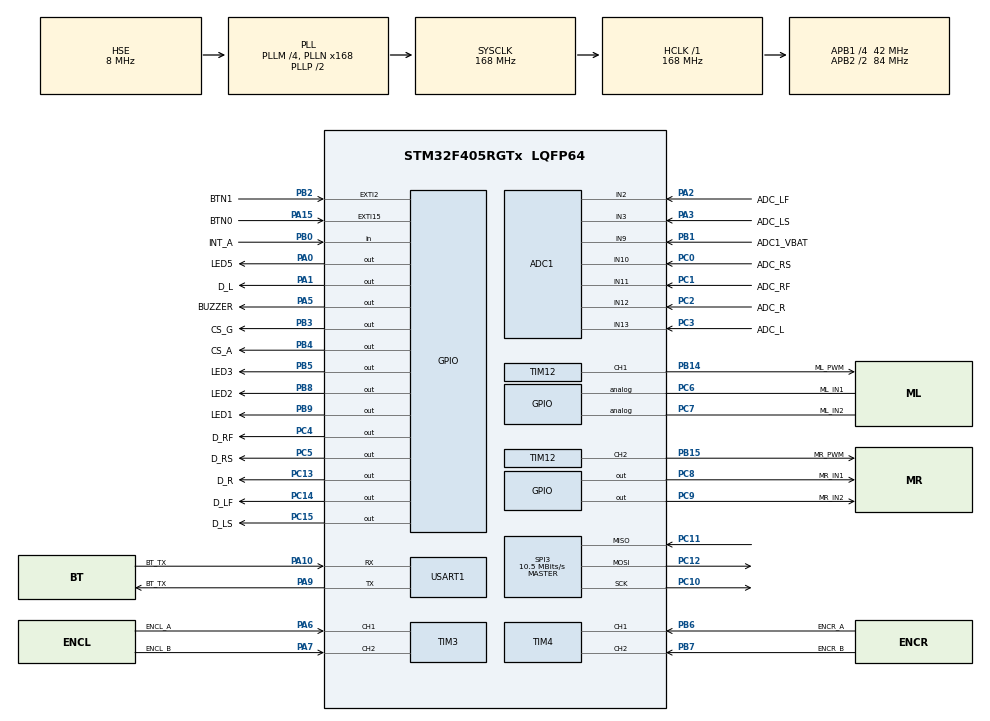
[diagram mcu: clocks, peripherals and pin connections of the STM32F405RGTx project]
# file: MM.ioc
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ADC1.Channel-8\#ChannelRegularConversion=ADC_CHANNEL_VREFINT
ADC1.ClockPrescaler=ADC_CLOCKPRESCALER_PCLK_DIV4
ADC1.ContinuousConvMode=DISABLE
ADC1.DMAContinuousRequests=DISABLE
ADC1.DataAlign=ADC_DATAALIGN_RIGHT
ADC1.DiscontinuousConvMode=DISABLE
ADC1.EOCSelection=EOC_SINGLE_CONV
ADC1.EnableAnalogWatchDog=false
ADC1.ExternalTrigConvEdge=ADC_EXTERNALTRIGCONVEDGE_NONE
ADC1.InjNumberOfConversion=0
ADC1.NbrOfConversion=1
ADC1.NbrOfConversionFlag=1
ADC1.Rank-8\#ChannelRegularConversion=1
ADC1.Resolution=ADC_RESOLUTION12b
ADC1.SamplingTime-8\#ChannelRegularConversion=ADC_SAMPLETIME_3CYCLES
ADC1.ScanConvMode=DISABLE
ADC1.master=1
Mcu.Family=STM32F4
Mcu.Name=STM32F405RGTx
Mcu.Package=LQFP64
NVIC.ADC_IRQn=true\:10\:0\:true
NVIC.EXTI15_10_IRQn=true\:15\:0\:true
NVIC.EXTI2_IRQn=true\:15\:0\:true
NVIC.PriorityGroup=NVIC_PRIORITYGROUP_4
NVIC.SPI3_IRQn=true\:5\:0\:true
NVIC.USART1_IRQn=true\:5\:0\:true
PA0-WKUP.GPIO_Label=LED5
PA0-WKUP.Signal=GPIO_Output
PA1.GPIO_Label=D_L
PA1.Signal=GPIO_Output
PA10.GPIO_Label=BT_TX
PA10.Mode=Asynchronous
PA10.Signal=USART1_RX
PA13.Mode=Serial-Wire
PA13.Signal=SYS_JTMS-SWDIO
PA14.Mode=Serial-Wire
PA14.Signal=SYS_JTCK-SWCLK
PA15.GPIO_Label=BTN0
PA15.Signal=GPXTI15
PA2.GPIO_Label=ADC_LF
PA2.Signal=ADCx_IN2
PA3.GPIO_Label=ADC_LS
PA3.Signal=ADCx_IN3
PA5.GPIO_Label=BUZZER
PA5.Signal=GPIO_Output
PA6.GPIO_Label=ENCL_A
PA6.Signal=S_TIM3_CH1
PA7.GPIO_Label=ENCL_B
PA7.Signal=S_TIM3_CH2
PA9.GPIO_Label=BT_TX
PA9.Mode=Asynchronous
PA9.Signal=USART1_TX
PB0.GPIO_Label=INT_A
PB0.Signal=GPIO_Input
PB1.GPIO_Label=ADC1_VBAT
PB1.Signal=ADCx_IN9
PB14.GPIO_Label=ML_PWM
PB14.Signal=S_TIM12_CH1
PB15.GPIO_Label=MR_PWM
PB15.Signal=S_TIM12_CH2
PB2.GPIO_Label=BTN1
PB2.Signal=GPXTI2
PB3.GPIO_Label=CS_G
PB3.Signal=GPIO_Output
PB4.GPIO_Label=CS_A
PB4.Signal=GPIO_Output
PB5.GPIO_Label=LED3
PB5.Signal=GPIO_Output
PB6.GPIO_Label=ENCR_A
PB6.Signal=S_TIM4_CH1
PB7.GPIO_Label=ENCR_B
PB7.Signal=S_TIM4_CH2
PB8.GPIO_Label=LED2
PB8.Signal=GPIO_Output
PB9.GPIO_Label=LED1
PB9.Signal=GPIO_Output
PC0.GPIO_Label=ADC_RS
PC0.Signal=ADCx_IN10
PC1.GPIO_Label=ADC_RF
PC1.Signal=ADCx_IN11
PC10.Mode=Full_Duplex_Master
PC10.Signal=SPI3_SCK
PC11.Mode=Full_Duplex_Master
PC11.Signal=SPI3_MISO
PC12.Mode=Full_Duplex_Master
PC12.Signal=SPI3_MOSI
PC13-ANTI_TAMP.GPIO_Label=D_R
PC13-ANTI_TAMP.Signal=GPIO_Output
PC14-OSC32_IN.GPIO_Label=D_LF
PC14-OSC32_IN.Signal=GPIO_Output
PC15-OSC32_OUT.GPIO_Label=D_LS
PC15-OSC32_OUT.Signal=GPIO_Output
PC2.GPIO_Label=ADC_R
PC2.Signal=ADCx_IN12
PC3.GPIO_Label=ADC_L
PC3.Signal=ADCx_IN13
PC4.GPIO_Label=D_RF
PC4.Signal=GPIO_Output
PC5.GPIO_Label=D_RS
PC5.Signal=GPIO_Output
PC6.GPIO_Label=ML_IN1
PC6.Signal=GPIO_Analog
PC7.GPIO_Label=ML_IN2
PC7.Signal=GPIO_Analog
PC8.GPIO_Label=MR_IN1
PC8.Signal=GPIO_Output
PC9.GPIO_Label=MR_IN2
PC9.Signal=GPIO_Output
PH0-OSC_IN.Mode=HSE-External-Oscillator
PH0-OSC_IN.Signal=RCC_OSC_IN
PH1-OSC_OUT.Mode=HSE-External-Oscillator
PH1-OSC_OUT.Signal=RCC_OSC_OUT
ProjectManager.HeapSize=0x400
ProjectManager.StackSize=0x200
ProjectManager.TargetToolchain=MDK-ARM V5
RCC.48MHZClocksFreq_Value=84000000
RCC.AHBFreq_Value=168000000
RCC.APB1CLKDivider=RCC_HCLK_DIV4
RCC.APB1Freq_Value=42000000
RCC.APB1TimFreq_Value=84000000
RCC.APB2CLKDivider=RCC_HCLK_DIV2
RCC.APB2Freq_Value=84000000
RCC.APB2TimFreq_Value=168000000
RCC.CortexFreq_Value=168000000
RCC.HCLKFreq_Value=168000000
RCC.HSE_VALUE=8000000
RCC.HSI_VALUE=16000000
RCC.LSE_VALUE=32768
RCC.PLLM=4
RCC.PLLN=168
RCC.PLLSourceVirtual=RCC_PLLSOURCE_HSE
RCC.SYSCLKFreq_VALUE=168000000
RCC.SYSCLKSource=RCC_SYSCLKSOURCE_PLLCLK
RCC.VCOOutputFreq_Value=336000000
SH.ADCx_IN10.0=ADC1_IN10,IN10
SH.ADCx_IN11.0=ADC1_IN11,IN11
SH.ADCx_IN12.0=ADC1_IN12,IN12
SH.ADCx_IN13.0=ADC1_IN13,IN13
SH.ADCx_IN2.0=ADC1_IN2,IN2
SH.ADCx_IN3.0=ADC1_IN3,IN3
SH.ADCx_IN9.0=ADC1_IN9,IN9
SH.S_TIM12_CH1.0=TIM12_CH1,PWM Generation1 CH1
SH.S_TIM12_CH2.0=TIM12_CH2,PWM Generation2 CH2
SH.S_TIM3_CH1.0=TIM3_CH1,Encoder_Interface
SH.S_TIM3_CH2.0=TIM3_CH2,Encoder_Interface
SH.S_TIM4_CH1.0=TIM4_CH1,Encoder_Interface
SH.S_TIM4_CH2.0=TIM4_CH2,Encoder_Interface
SPI3.BaudRatePrescaler=SPI_BAUDRATEPRESCALER_4
SPI3.CalculateBaudRate=10.5 MBits/s
SPI3.Mode=SPI_MODE_MASTER
TIM12.Channel-PWM\ Generation2\ CH2=TIM_CHANNEL_2
VP_ADC1_TempSens_Input.Mode=IN-TempSens
VP_ADC1_Vref_Input.Mode=IN-Vrefint
board=MM

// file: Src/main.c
/**
  ******************************************************************************
  * File Name          : main.c
  * Description        : Main program body
  ******************************************************************************
  *
  * COPYRIGHT(c) 2016 STMicroelectronics
  *
  * Redistribution and use in source and binary forms, with or without modification,
  * are permitted provided that the following conditions are met:
  *   1. Redistributions of source code must retain the above copyright notice,
  *      this list of conditions and the following disclaimer.
  *   2. Redistributions in binary form must reproduce the above copyright notice,
  *      this list of conditions and the following disclaimer in the documentation
  *      and/or other materials provided with the distribution.
  *   3. Neither the name of STMicroelectronics nor the names of its contributors
  *      may be used to endorse or promote products derived from this software
  *      without specific prior written permission.
  *
  * THIS SOFTWARE IS PROVIDED BY THE COPYRIGHT HOLDERS AND CONTRIBUTORS "AS IS"
  * AND ANY EXPRESS OR IMPLIED WARRANTIES, INCLUDING, BUT NOT LIMITED TO, THE
  * IMPLIED WARRANTIES OF MERCHANTABILITY AND FITNESS FOR A PARTICULAR PURPOSE ARE
  * DISCLAIMED. IN NO EVENT SHALL THE COPYRIGHT HOLDER OR CONTRIBUTORS BE LIABLE
  * FOR ANY DIRECT, INDIRECT, INCIDENTAL, SPECIAL, EXEMPLARY, OR CONSEQUENTIAL
  * DAMAGES (INCLUDING, BUT NOT LIMITED TO, PROCUREMENT OF SUBSTITUTE GOODS OR
  * SERVICES; LOSS OF USE, DATA, OR PROFITS; OR BUSINESS INTERRUPTION) HOWEVER
  * CAUSED AND ON ANY THEORY OF LIABILITY, WHETHER IN CONTRACT, STRICT LIABILITY,
  * OR TORT (INCLUDING NEGLIGENCE OR OTHERWISE) ARISING IN ANY WAY OUT OF THE USE
  * OF THIS SOFTWARE, EVEN IF ADVISED OF THE POSSIBILITY OF SUCH DAMAGE.
  *
  ******************************************************************************
  */
#include "stm32f4xx_hal.h"

ADC_HandleTypeDef hadc1;

SPI_HandleTypeDef hspi3;

TIM_HandleTypeDef htim3;
TIM_HandleTypeDef htim4;
TIM_HandleTypeDef htim12;

UART_HandleTypeDef huart1;

/* USER CODE BEGIN PV */
/* Private variables ---------------------------------------------------------*/
#define BUFFERSIZE 16
/* USER CODE END PV */

void SystemClock_Config(void);
static void MX_GPIO_Init(void);
static void MX_ADC1_Init(void);
static void MX_SPI3_Init(void);
static void MX_TIM3_Init(void);
static void MX_TIM4_Init(void);
static void MX_TIM12_Init(void);
static void MX_USART1_UART_Init(void);

void HAL_TIM_MspPostInit(TIM_HandleTypeDef *htim);

/* USER CODE BEGIN PFP */
/* Private function prototypes -----------------------------------------------*/

/* USER CODE END PFP */

/* USER CODE BEGIN 0 */

uint8_t aTxBuffer[] = "****SPI - Two Boards communication based on DMA **** SPI Message ******** SPI Message ******** SPI Message ****";
uint8_t aRxBuffer[BUFFERSIZE];
/* USER CODE END 0 */

int main(void)
{

  /* MCU Configuration----------------------------------------------------------*/

  /* Reset of all peripherals, Initializes the Flash interface and the Systick. */
  HAL_Init();

  /* Configure the system clock */
  SystemClock_Config();

  /* Initialize all configured peripherals */
  MX_GPIO_Init();
  MX_ADC1_Init();
  MX_SPI3_Init();
  MX_TIM3_Init();
  MX_TIM4_Init();
  MX_TIM12_Init();
  MX_USART1_UART_Init();

  /* Infinite loop */
  while (1)
  {
		HAL_SPI_TransmitReceive_DMA(&hspi3, (uint8_t*)aTxBuffer, (uint8_t *)aRxBuffer, BUFFERSIZE);
	HAL_Delay(2000);
  }

}

/** System Clock Configuration
*/
void SystemClock_Config(void)
{

  RCC_OscInitTypeDef RCC_OscInitStruct;
  RCC_ClkInitTypeDef RCC_ClkInitStruct;

  __PWR_CLK_ENABLE();

  __HAL_PWR_VOLTAGESCALING_CONFIG(PWR_REGULATOR_VOLTAGE_SCALE1);

  RCC_OscInitStruct.OscillatorType = RCC_OSCILLATORTYPE_HSE;
  RCC_OscInitStruct.HSEState = RCC_HSE_ON;
  RCC_OscInitStruct.PLL.PLLState = RCC_PLL_ON;
  RCC_OscInitStruct.PLL.PLLSource = RCC_PLLSOURCE_HSE;
  RCC_OscInitStruct.PLL.PLLM = 4;
  RCC_OscInitStruct.PLL.PLLN = 168;
  RCC_OscInitStruct.PLL.PLLP = RCC_PLLP_DIV2;
  RCC_OscInitStruct.PLL.PLLQ = 4;
  HAL_RCC_OscConfig(&RCC_OscInitStruct);

  RCC_ClkInitStruct.ClockType = RCC_CLOCKTYPE_HCLK|RCC_CLOCKTYPE_SYSCLK
                              |RCC_CLOCKTYPE_PCLK1|RCC_CLOCKTYPE_PCLK2;
  RCC_ClkInitStruct.SYSCLKSource = RCC_SYSCLKSOURCE_PLLCLK;
  RCC_ClkInitStruct.AHBCLKDivider = RCC_SYSCLK_DIV1;
  RCC_ClkInitStruct.APB1CLKDivider = RCC_HCLK_DIV4;
  RCC_ClkInitStruct.APB2CLKDivider = RCC_HCLK_DIV2;
  HAL_RCC_ClockConfig(&RCC_ClkInitStruct, FLASH_LATENCY_5);

  HAL_SYSTICK_Config(HAL_RCC_GetHCLKFreq()/1000);

  HAL_SYSTICK_CLKSourceConfig(SYSTICK_CLKSOURCE_HCLK);

  /* SysTick_IRQn interrupt configuration */
  HAL_NVIC_SetPriority(SysTick_IRQn, 0, 0);
}

/* ADC1 init function */
void MX_ADC1_Init(void)
{

  ADC_ChannelConfTypeDef sConfig;

    /**Configure the global features of the ADC (Clock, Resolution, Data Alignment and number of conversion)
    */
  hadc1.Instance = ADC1;
  hadc1.Init.ClockPrescaler = ADC_CLOCKPRESCALER_PCLK_DIV4;
  hadc1.Init.Resolution = ADC_RESOLUTION12b;
  hadc1.Init.ScanConvMode = DISABLE;
  hadc1.Init.ContinuousConvMode = DISABLE;
  hadc1.Init.DiscontinuousConvMode = DISABLE;
  hadc1.Init.ExternalTrigConvEdge = ADC_EXTERNALTRIGCONVEDGE_NONE;
  hadc1.Init.DataAlign = ADC_DATAALIGN_RIGHT;
  hadc1.Init.NbrOfConversion = 1;
  hadc1.Init.DMAContinuousRequests = DISABLE;
  hadc1.Init.EOCSelection = EOC_SINGLE_CONV;
  HAL_ADC_Init(&hadc1);

    /**Configure for the selected ADC regular channel its corresponding rank in the sequencer and its sample time.
    */
  sConfig.Channel = ADC_CHANNEL_VREFINT;
  sConfig.Rank = 1;
  sConfig.SamplingTime = ADC_SAMPLETIME_3CYCLES;
  HAL_ADC_ConfigChannel(&hadc1, &sConfig);

}

/* SPI3 init function */
void MX_SPI3_Init(void)
{

  hspi3.Instance = SPI3;
  hspi3.Init.Mode = SPI_MODE_MASTER;
  hspi3.Init.Direction = SPI_DIRECTION_2LINES;
  hspi3.Init.DataSize = SPI_DATASIZE_8BIT;
  hspi3.Init.CLKPolarity = SPI_POLARITY_LOW;
  hspi3.Init.CLKPhase = SPI_PHASE_1EDGE;
  hspi3.Init.NSS = SPI_NSS_SOFT;
  hspi3.Init.BaudRatePrescaler = SPI_BAUDRATEPRESCALER_4;
  hspi3.Init.FirstBit = SPI_FIRSTBIT_MSB;
  hspi3.Init.TIMode = SPI_TIMODE_DISABLED;
  hspi3.Init.CRCCalculation = SPI_CRCCALCULATION_DISABLED;
  hspi3.Init.CRCPolynomial = 10;
  HAL_SPI_Init(&hspi3);

}

/* TIM3 init function */
void MX_TIM3_Init(void)
{

  TIM_Encoder_InitTypeDef sConfig;
  TIM_MasterConfigTypeDef sMasterConfig;

  htim3.Instance = TIM3;
  htim3.Init.Prescaler = 0;
  htim3.Init.CounterMode = TIM_COUNTERMODE_UP;
  htim3.Init.Period = 0;
  htim3.Init.ClockDivision = TIM_CLOCKDIVISION_DIV1;
  sConfig.EncoderMode = TIM_ENCODERMODE_TI1;
  sConfig.IC1Polarity = TIM_ICPOLARITY_RISING;
  sConfig.IC1Selection = TIM_ICSELECTION_DIRECTTI;
  sConfig.IC1Prescaler = TIM_ICPSC_DIV1;
  sConfig.IC1Filter = 0;
  sConfig.IC2Polarity = TIM_ICPOLARITY_RISING;
  sConfig.IC2Selection = TIM_ICSELECTION_DIRECTTI;
  sConfig.IC2Prescaler = TIM_ICPSC_DIV1;
  sConfig.IC2Filter = 0;
  HAL_TIM_Encoder_Init(&htim3, &sConfig);

  sMasterConfig.MasterOutputTrigger = TIM_TRGO_RESET;
  sMasterConfig.MasterSlaveMode = TIM_MASTERSLAVEMODE_DISABLE;
  HAL_TIMEx_MasterConfigSynchronization(&htim3, &sMasterConfig);

}

/* TIM4 init function */
void MX_TIM4_Init(void)
{

  TIM_Encoder_InitTypeDef sConfig;
  TIM_MasterConfigTypeDef sMasterConfig;

  htim4.Instance = TIM4;
  htim4.Init.Prescaler = 0;
  htim4.Init.CounterMode = TIM_COUNTERMODE_UP;
  htim4.Init.Period = 0;
  htim4.Init.ClockDivision = TIM_CLOCKDIVISION_DIV1;
  sConfig.EncoderMode = TIM_ENCODERMODE_TI1;
  sConfig.IC1Polarity = TIM_ICPOLARITY_RISING;
  sConfig.IC1Selection = TIM_ICSELECTION_DIRECTTI;
  sConfig.IC1Prescaler = TIM_ICPSC_DIV1;
  sConfig.IC1Filter = 0;
  sConfig.IC2Polarity = TIM_ICPOLARITY_RISING;
  sConfig.IC2Selection = TIM_ICSELECTION_DIRECTTI;
  sConfig.IC2Prescaler = TIM_ICPSC_DIV1;
  sConfig.IC2Filter = 0;
  HAL_TIM_Encoder_Init(&htim4, &sConfig);

  sMasterConfig.MasterOutputTrigger = TIM_TRGO_RESET;
  sMasterConfig.MasterSlaveMode = TIM_MASTERSLAVEMODE_DISABLE;
  HAL_TIMEx_MasterConfigSynchronization(&htim4, &sMasterConfig);

}

/* TIM12 init function */
void MX_TIM12_Init(void)
{

  TIM_OC_InitTypeDef sConfigOC;

  htim12.Instance = TIM12;
  htim12.Init.Prescaler = 0;
  htim12.Init.CounterMode = TIM_COUNTERMODE_UP;
  htim12.Init.Period = 0;
  htim12.Init.ClockDivision = TIM_CLOCKDIVISION_DIV1;
  HAL_TIM_PWM_Init(&htim12);

  sConfigOC.OCMode = TIM_OCMODE_PWM1;
  sConfigOC.Pulse = 0;
  sConfigOC.OCPolarity = TIM_OCPOLARITY_HIGH;
  sConfigOC.OCFastMode = TIM_OCFAST_DISABLE;
  HAL_TIM_PWM_ConfigChannel(&htim12, &sConfigOC, TIM_CHANNEL_1);

  HAL_TIM_PWM_ConfigChannel(&htim12, &sConfigOC, TIM_CHANNEL_2);

  HAL_TIM_MspPostInit(&htim12);

}

/* USART1 init function */
void MX_USART1_UART_Init(void)
{

  huart1.Instance = USART1;
  huart1.Init.BaudRate = 115200;
  huart1.Init.WordLength = UART_WORDLENGTH_8B;
  huart1.Init.StopBits = UART_STOPBITS_1;
  huart1.Init.Parity = UART_PARITY_NONE;
  huart1.Init.Mode = UART_MODE_TX_RX;
  huart1.Init.HwFlowCtl = UART_HWCONTROL_NONE;
  huart1.Init.OverSampling = UART_OVERSAMPLING_16;
  HAL_UART_Init(&huart1);

}

/** Configure pins as
        * Analog
        * Input
        * Output
        * EVENT_OUT
        * EXTI
*/
void MX_GPIO_Init(void)
{

  GPIO_InitTypeDef GPIO_InitStruct;

  /* GPIO Ports Clock Enable */
  __GPIOC_CLK_ENABLE();
  __GPIOH_CLK_ENABLE();
  __GPIOA_CLK_ENABLE();
  __GPIOB_CLK_ENABLE();

  /*Configure GPIO pin Output Level */
  HAL_GPIO_WritePin(GPIOC, D_R_Pin|D_LF_Pin|D_LS_Pin|D_RF_Pin
                          |D_RS_Pin|MR_IN1_Pin|MR_IN2_Pin, GPIO_PIN_RESET);

  /*Configure GPIO pin Output Level */
  HAL_GPIO_WritePin(GPIOA, LED5_Pin|D_L_Pin|BUZZER_Pin, GPIO_PIN_RESET);

  /*Configure GPIO pin Output Level */
  HAL_GPIO_WritePin(GPIOB, CS_G_Pin|CS_A_Pin|LED3_Pin|LED2_Pin
                          |LED1_Pin, GPIO_PIN_RESET);

  /*Configure GPIO pins : D_R_Pin D_LF_Pin D_LS_Pin D_RF_Pin
                           D_RS_Pin MR_IN1_Pin MR_IN2_Pin */
  GPIO_InitStruct.Pin = D_R_Pin|D_LF_Pin|D_LS_Pin|D_RF_Pin
                          |D_RS_Pin|MR_IN1_Pin|MR_IN2_Pin;
  GPIO_InitStruct.Mode = GPIO_MODE_OUTPUT_PP;
  GPIO_InitStruct.Pull = GPIO_NOPULL;
  GPIO_InitStruct.Speed = GPIO_SPEED_LOW;
  HAL_GPIO_Init(GPIOC, &GPIO_InitStruct);

  /*Configure GPIO pins : LED5_Pin D_L_Pin BUZZER_Pin */
  GPIO_InitStruct.Pin = LED5_Pin|D_L_Pin|BUZZER_Pin;
  GPIO_InitStruct.Mode = GPIO_MODE_OUTPUT_PP;
  GPIO_InitStruct.Pull = GPIO_NOPULL;
  GPIO_InitStruct.Speed = GPIO_SPEED_LOW;
  HAL_GPIO_Init(GPIOA, &GPIO_InitStruct);

  /*Configure GPIO pin : INT_A_Pin */
  GPIO_InitStruct.Pin = INT_A_Pin;
  GPIO_InitStruct.Mode = GPIO_MODE_INPUT;
  GPIO_InitStruct.Pull = GPIO_NOPULL;
  HAL_GPIO_Init(INT_A_GPIO_Port, &GPIO_InitStruct);

  /*Configure GPIO pin : BTN1_Pin */
  GPIO_InitStruct.Pin = BTN1_Pin;
  GPIO_InitStruct.Mode = GPIO_MODE_IT_RISING;
  GPIO_InitStruct.Pull = GPIO_NOPULL;
  HAL_GPIO_Init(BTN1_GPIO_Port, &GPIO_InitStruct);

  /*Configure GPIO pins : ML_IN1_Pin ML_IN2_Pin */
  GPIO_InitStruct.Pin = ML_IN1_Pin|ML_IN2_Pin;
  GPIO_InitStruct.Mode = GPIO_MODE_ANALOG;
  GPIO_InitStruct.Pull = GPIO_NOPULL;
  HAL_GPIO_Init(GPIOC, &GPIO_InitStruct);

  /*Configure GPIO pin : BTN0_Pin */
  GPIO_InitStruct.Pin = BTN0_Pin;
  GPIO_InitStruct.Mode = GPIO_MODE_IT_RISING;
  GPIO_InitStruct.Pull = GPIO_NOPULL;
  HAL_GPIO_Init(BTN0_GPIO_Port, &GPIO_InitStruct);

  /*Configure GPIO pins : CS_G_Pin CS_A_Pin LED3_Pin LED2_Pin
                           LED1_Pin */
  GPIO_InitStruct.Pin = CS_G_Pin|CS_A_Pin|LED3_Pin|LED2_Pin
                          |LED1_Pin;
  GPIO_InitStruct.Mode = GPIO_MODE_OUTPUT_PP;
  GPIO_InitStruct.Pull = GPIO_NOPULL;
  GPIO_InitStruct.Speed = GPIO_SPEED_LOW;
  HAL_GPIO_Init(GPIOB, &GPIO_InitStruct);

  /* EXTI interrupt init*/
  HAL_NVIC_SetPriority(EXTI2_IRQn, 15, 0);
  HAL_NVIC_EnableIRQ(EXTI2_IRQn);

  HAL_NVIC_SetPriority(EXTI15_10_IRQn, 15, 0);
  HAL_NVIC_EnableIRQ(EXTI15_10_IRQn);

}

/************************ (C) COPYRIGHT STMicroelectronics *****END OF FILE****/
